# PIC32CK2051SG00064 device description
Architecture: CORTEX-M33; Family: PIC32CK; Series: PIC32CKSG00
Registers are 32-bit, read-write, reset 0x0 unless marked. A register's access mark holds for its fields unless they carry their own. Offsets are from the block's base; [hi:lo] are bit positions; {n}, {i} and the like mark numbered series; 'fields as' and 'values as' point back to an identical list.

## FUSES_DALCFG — Defines FUSE parameters
Instances: FUSES_DALCFG 0x0A004000
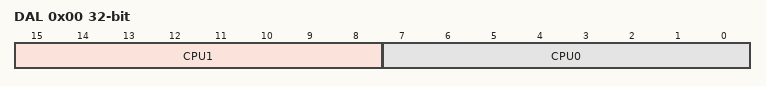
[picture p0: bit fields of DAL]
0x00 DAL — Debug Access Level
  [15:8] CPU1 — HSM DAL Elevation Value
    129=DAL0 (FCW_DAL0_VALUE); 153=DAL1 (FCW_DAL1_VALUE); 219=DAL2 (FCW_DAL2_VALUE)
  [7:0] CPU0 — Host DAL Elevation Value
    values as CPU1

## FUSES_USERCFG1 — Defines FUSE parameters
Instances: FUSES_USERCFG1 0x0A000000, FUSES_USERCFG2 0x0A008000
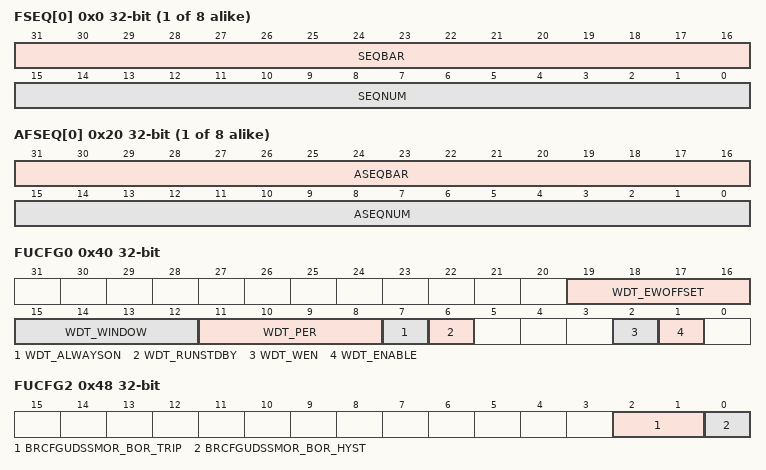
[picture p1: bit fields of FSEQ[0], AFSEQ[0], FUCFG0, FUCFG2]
{0x0+4i} FSEQ[{i}] (i=0..7) reset not defined — Flash Sequence Number
  [31:16] SEQBAR — Sequence Number Bar (Negeated)
  [15:0] SEQNUM — Sequence Number
{0x20+4i} AFSEQ[{i}] (i=0..7) reset not defined — Alternate Flash Sequence Number
  [31:16] ASEQBAR — Alternate Sequence Number Bar (Negeated)
  [15:0] ASEQNUM — Alternate Sequence Number
0x40 FUCFG0 reset not defined — WDT Configuration
  [19:16] WDT_EWOFFSET — Early Warning Interrupt Time Offset
  [15:12] WDT_WINDOW — Window Mode Time-out Period
  [11:8] WDT_PER — Time-out Period
  [7] WDT_ALWAYSON — Always On
  [6] WDT_RUNSTDBY — Run in Standby
  [2] WDT_WEN — Window Mode Enable
  [1] WDT_ENABLE — Enable
0x44 FUCFG1 reset not defined — User Configuration 1 (System Bus Configuration)
0x48 FUCFG2 reset not defined — User Configuration 2 (Deep Sleep SMOR Configuration)
  [2:1] BRCFGUDSSMOR_BOR_TRIP — BOT Trip Points
  [0] BRCFGUDSSMOR_BOR_HYST — BOT Trip Hystersis
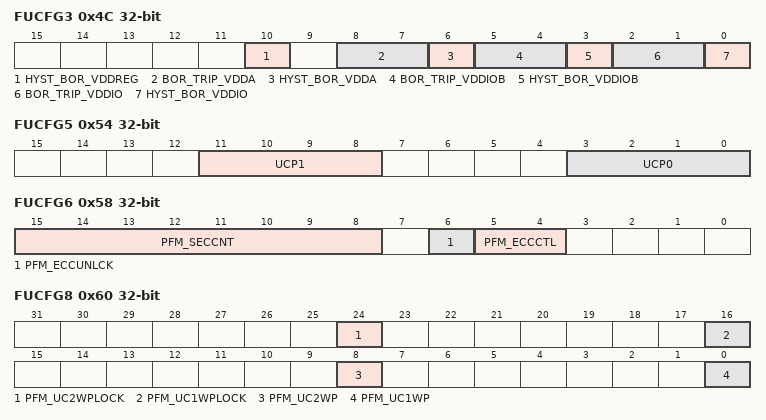
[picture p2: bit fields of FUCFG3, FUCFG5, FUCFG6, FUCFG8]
0x4C FUCFG3 reset not defined — User Configuration 2 (SMOR Configuration)
  [10] HYST_BOR_VDDREG — BOR Trip Point Hystersis for VDDREG
  [8:7] BOR_TRIP_VDDA — BOR Trip Points for VDDANA
  [6] HYST_BOR_VDDA — BOR Trip Point Hystersis for VDDANA
  [5:4] BOR_TRIP_VDDIOB — BOR Trip Points for VDDIOB
  [3] HYST_BOR_VDDIOB — BOR Trip Point Hystersis for VDDIOB
  [2:1] BOR_TRIP_VDDIO — BOR Trip Points for VDDIO
  [0] HYST_BOR_VDDIO — BOR Trip Point Hystersis for VDDIO
0x54 FUCFG5 — User Configuration 5 (VREG Charge Pump Configuration)
  [11:8] UCP1 — User charge pump setting
  [3:0] UCP0 — User charge pump setting
0x58 FUCFG6 reset not defined — User Configuration 6 (FCR ECCCTRL Configuration)
  [15:8] PFM_SECCNT — Flash SEC Count
  [6] PFM_ECCUNLCK — ECC Mode Control Unlock
  [5:4] PFM_ECCCTL — ECC Mode Control
0x5C FUCFG7 reset not defined — User Configuration 7 (FCR CTRLB Configuration)
  [1] PFM_TEMP — NVM Operating Temperature Read Mode
0x60 FUCFG8 reset not defined — User Configuration 8 (FCW CWP Configuration)
  [24] PFM_UC2WPLOCK — User Configuration Page 2 Write Protection Lock
  [16] PFM_UC1WPLOCK — User Configuration Page 1 Write Protection Lock
  [8] PFM_UC2WP — User Configuration Page 2 Write Protect
  [0] PFM_UC1WP — User Configuration Page 1 Write Protect
0x64 FUCFG9 reset not defined — User Configuration 9 (RAM BISR and ECC Configuraiton)
0x68 FUCFG10 reset not defined — IDAU_NONSECA
  [31:0] BOOTROM_NONSECA
0x6C FUCFG11 reset not defined — IDAU_NONSECB
  [31:0] BOOTROM_NONSECB
0x70 FUCFG12 reset not defined — IDAU_NONSECC
  [31:0] BOOTROM_NONSECC
0x74 FUCFG13 reset not defined — IDAU_NONSECAHB
  [31:0] BOOTROM_NONSECAHB
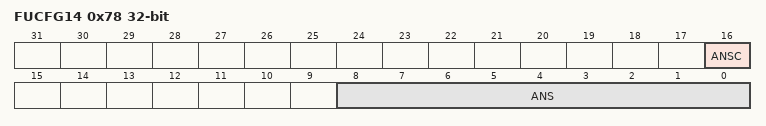
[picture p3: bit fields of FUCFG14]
0x78 FUCFG14 reset not defined — PFM IDAU Configuration
  [16] ANSC — Non-secure callable Flash application size
  [8:0] ANS — Non-secure Flash application size
0x7C FUCFG15 reset not defined — RAM IDAU Configuration
  [6:0] RNS — Non-secure RAM size
0x80 FUCFG16 reset not defined — User Configuration 16 (HSM Firmware Metadata 0 Address)
  [31:0] HSM_PTRMETA0 — HSM Firmware Metadata pointer 0
0xA0 FUCFG24 reset not defined — User Configuration 24 (HSM Firmware Metadata 1 Address)
  [31:0] HSM_PTRMETA1 — HSM Firmware Metadata pointer 1

## GCLK — Generic Clock Generator
Instances: GCLK 0x44010000
0x00 CTRLA 8-bit (WSYNC) — Control
  [0] SWRST — Software Reset
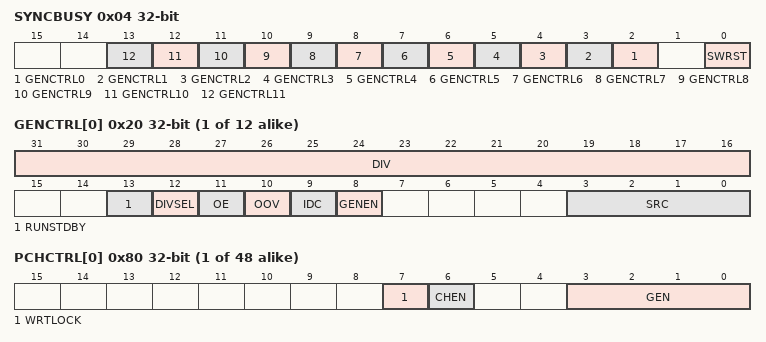
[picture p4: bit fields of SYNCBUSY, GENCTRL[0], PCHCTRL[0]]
0x04 SYNCBUSY ro — Synchronization Busy
  [n+2] GENCTRL{n} (n=0..11) — Generic Clock Generator Control {n} Synchronization Busy bit
  [0] SWRST — Software Reset Synchronization Busy bit
{0x20+4i} GENCTRL[{i}] (i=0..11) (WSYNC) — Generic Clock Generator Control
  [31:16] DIV — Division Factor
  [13] RUNSTDBY — Run in Standby
  [12] DIVSEL — Divide Selection
    0=DIV1 (Divide input directly by divider factor); 1=DIV2 (Divide input by 2^(divider factor+ 1))
  [11] OE — Output Enable
  [10] OOV — Output Off Value
  [9] IDC — Improve Duty Cycle
  [8] GENEN — Generic Clock Generator Enable
  [3:0] SRC — Source Select
    0=XOSC (XOSC0 oscillator output); 1=GCLKIN (Generator input pad); 2=GCLKGEN1 (Generic clock generator 1 output); 3=OSCULP32K (OSCULP32K oscillator output); 4=XOSC32K (XOSC32K oscillator output); 5=DFLL (DFLL output); 6=PLL0_0 (Frac Divider PLL0 output 0); {v}=PLL0_{v-6} (PLL0 output {v-6}) (v=7..11)
{0x80+4i} PCHCTRL[{i}] (i=0..47) — Peripheral Clock Control
  [7] WRTLOCK — Write Lock
  [6] CHEN — Channel Enable
  [3:0] GEN — Generic Clock Generator
    {v}=GCLK{v} (Generic clock generator {v}) (v=0..11)

## Notices in the file
Copyright (c) 2021 Microchip Technology Inc.
SPDX-License-Identifier: Apache-2.0
Licensed under the Apache License, Version 2.0 (the "License");
you may not use this file except in compliance with the License.
You may obtain a copy of the License at
http://www.apache.org/licenses/LICENSE-2.0
Unless required by applicable law or agreed to in writing, software
distributed under the License is distributed on an "AS IS" BASIS,
WITHOUT WARRANTIES OR CONDITIONS OF ANY KIND, either express or implied.
See the License for the specific language governing permissions and
limitations under the License.
